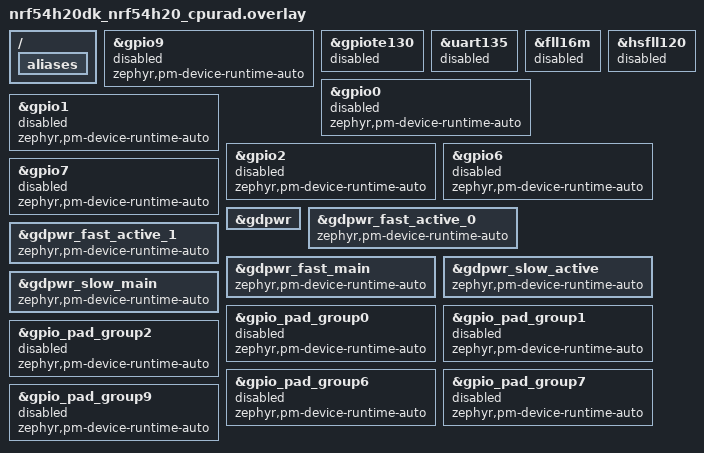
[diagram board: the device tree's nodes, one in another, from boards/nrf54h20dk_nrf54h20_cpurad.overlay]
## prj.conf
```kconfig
CONFIG_PM=y
CONFIG_POWEROFF=y
CONFIG_CONSOLE=n
CONFIG_UART_CONSOLE=n
CONFIG_SERIAL=n
CONFIG_GPIO=n
CONFIG_BOOT_BANNER=n
CONFIG_PM_DEVICE=y
CONFIG_PM_DEVICE_RUNTIME=y
```

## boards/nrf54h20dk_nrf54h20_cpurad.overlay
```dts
/*
 * Copyright (c) 2024 Nordic Semiconductor ASA
 *
 * SPDX-License-Identifier: LicenseRef-Nordic-5-Clause
 */

/ {
	aliases {
		/*led = &led1;*/
		/delete-property/ led1;
	};

/*
	leds {
		compatible = "gpio-leds";
		led1: led_1 {
			gpios = <&gpio9 1 GPIO_ACTIVE_HIGH>;
			label = "Green LED 1";
		};
	};
*/
};

&gpio9 {
	status = "disabled";
};

&gpiote130 {
	status = "disabled";
};

&uart135 {
	status = "disabled";
	/delete-property/memory-regions;
};

// Attempts

&fll16m {
	status = "disabled";
};

&hsfll120 {
	status = "disabled";
};

&gpio0 {
	status = "disabled";
	zephyr,pm-device-runtime-auto;
};

&gpio1 {
	status = "disabled";
	zephyr,pm-device-runtime-auto;
};

&gpio2 {
	status = "disabled";
	zephyr,pm-device-runtime-auto;
};

&gpio6 {
	status = "disabled";
	zephyr,pm-device-runtime-auto;
};

&gpio7 {
	status = "disabled";
	zephyr,pm-device-runtime-auto;
};

&gpio9 {
	status = "disabled";
	zephyr,pm-device-runtime-auto;
};

&gdpwr {
	status = "okay";
};

&gdpwr_fast_active_0 {
	status = "okay";
	zephyr,pm-device-runtime-auto;
};

&gdpwr_fast_active_1 {
	status = "okay";
	zephyr,pm-device-runtime-auto;
};

&gdpwr_fast_main {
	status = "okay";
	zephyr,pm-device-runtime-auto;
};

&gdpwr_slow_active {
	status = "okay";
	zephyr,pm-device-runtime-auto;
};

&gdpwr_slow_main {
	status = "okay";
	zephyr,pm-device-runtime-auto;
};

&gpio_pad_group0 {
	status = "disabled";
	zephyr,pm-device-runtime-auto;
};

&gpio_pad_group1 {
	status = "disabled";
	zephyr,pm-device-runtime-auto;
};

&gpio_pad_group2 {
	status = "disabled";
	zephyr,pm-device-runtime-auto;
};

&gpio_pad_group6 {
	status = "disabled";
	zephyr,pm-device-runtime-auto;
};

&gpio_pad_group7 {
	status = "disabled";
	zephyr,pm-device-runtime-auto;
};

&gpio_pad_group9 {
	status = "disabled";
	zephyr,pm-device-runtime-auto;
};
```

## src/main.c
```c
/*
 * Copyright (c) 2024 Nordic Semiconductor ASA
 *
 * SPDX-License-Identifier: LicenseRef-Nordic-5-Clause
 */
#include <zephyr/kernel.h>
#include <zephyr/drivers/gpio.h>

//static const struct gpio_dt_spec led = GPIO_DT_SPEC_GET(DT_ALIAS(led), gpios);


int main(void)
{
	//gpio_pin_configure_dt(&led, GPIO_OUTPUT_INACTIVE);
	k_sleep(K_FOREVER);

	return 0;
}
```
